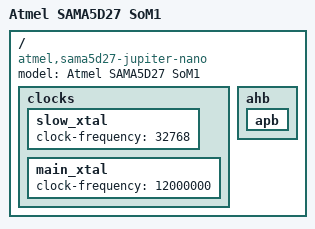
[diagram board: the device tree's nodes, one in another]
// SPDX-License-Identifier: (GPL-2.0+ OR MIT)
/*
 * at91-sama5d27_jupiter_nano.dtsi - Device Tree include file for Jupiter Nano board
 *
 * Contributed by: Shashank Kulkarni
 * 
 * Jupiter Nano is an open source hardware board based on the Microchip SAMA5D27
 * processor with 1 Gbit LPDDR2 integrated inside the package. This board is designed
 * by Starcat.io.
 *
 *
 *  Copyright (c) 2017, Microchip Technology Inc.
 *                2017 Cristian Birsan <cristian.birsan@microchip.com>
 *                2017 Claudiu Beznea <claudiu.beznea@microchip.com>
 */
#include "sama5d2.dtsi"
#include "sama5d2-pinfunc.h"
#include <dt-bindings/gpio/gpio.h>

/ {
	model = "Atmel SAMA5D27 SoM1";
	compatible = "atmel,sama5d27-jupiter-nano", "atmel,sama5d27", "atmel,sama5d2", "atmel,sama5";

	clocks {
		slow_xtal {
			clock-frequency = <32768>;
		};

		main_xtal {
			clock-frequency = <12000000>;
		};
	};

	ahb {
		apb {

		};
	};
};
